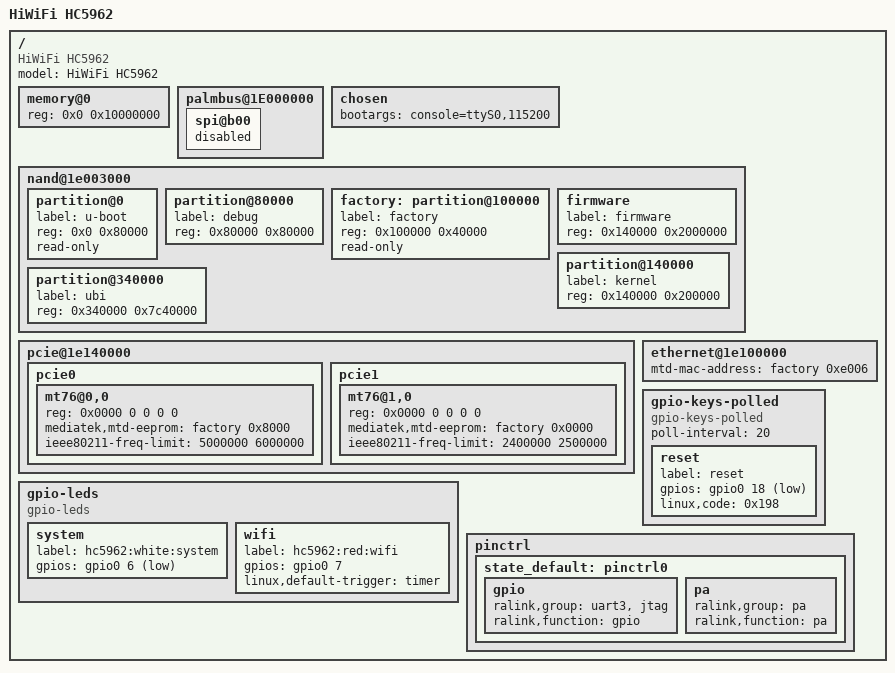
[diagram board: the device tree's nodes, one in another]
/dts-v1/;

/include/ "mt7621.dtsi"

/ {
	compatible = "HiWiFi HC5962", "mediatek,mt7621-soc";
	model = "HiWiFi HC5962";

	memory@0 {
		device_type = "memory";
		reg = <0x0 0x10000000>;
	};

	palmbus@1E000000 {
		spi@b00 {
			status="disabled";
		};
	};

	chosen {
		bootargs = "console=ttyS0,115200";
	};

	nand@1e003000 {
		status = "okay";

		partition@0 {
			label = "u-boot";
			reg = <0x0 0x80000>;
			read-only;
		};

		partition@80000 {
			label = "debug";
			reg = <0x80000 0x80000>;
		};

		factory: partition@100000 {
			label = "factory";
			reg = <0x100000 0x40000>;
			read-only;
		};
		
		firmware {
			label = "firmware";
			reg = <0x140000 0x2000000>;
		};

		partition@140000 {
			label = "kernel";
			reg = <0x140000 0x200000>;
		};

		partition@340000 {
			label = "ubi";
			reg = <0x340000 0x7c40000>;
		};
	};

	pcie@1e140000 {
		status = "okay";

		pcie0 {
			mt76@0,0 {
				reg = <0x0000 0 0 0 0>;
				device_type = "pci";
				mediatek,mtd-eeprom = <&factory 0x8000>;
				ieee80211-freq-limit = <5000000 6000000>;
			};
		};

		pcie1 {
			mt76@1,0 {
				reg = <0x0000 0 0 0 0>;
				device_type = "pci";
				mediatek,mtd-eeprom = <&factory 0x0000>;
				ieee80211-freq-limit = <2400000 2500000>;
			};
		};
	};

	ethernet@1e100000 {
		mtd-mac-address = <&factory 0xe006>;
	};	

	gpio-leds {
		compatible = "gpio-leds";

		system {
			label = "hc5962:white:system";
			gpios = <&gpio0 6 1>;
		};	
		
		wifi {
			label = "hc5962:red:wifi";
			gpios = <&gpio0 7 0>;
			linux,default-trigger = "timer";
		};
	};

	gpio-keys-polled {
		compatible = "gpio-keys-polled";
		#address-cells = <1>;
		#size-cells = <0>;
		poll-interval = <20>;

		reset {
			label = "reset";
			gpios = <&gpio0 18 1>;
			linux,code = <0x198>;
		};
	};

	pinctrl {
		state_default: pinctrl0 {
			gpio {
				ralink,group = "uart3", "jtag";
				ralink,function = "gpio";
			};

			pa {
				ralink,group = "pa";
				ralink,function = "pa";
			};
		};
	};
};
